# Espressif register map
File version: 1.0
CPU: Xtensa LX6 1, little endian, no MPU, FPU, 3 interrupt priority bits
Registers are 32-bit, access not given, reset 0x0 unless marked. A register's access mark holds for its fields unless they carry their own. Offsets are from the block's base; [hi:lo] are bit positions; {n}, {i} and the like mark numbered series.

## DPORT
Base 0x3FF00000
0x00 PRO_BOOT_REMAP_CTRL — DPORT_PRO_BOOT_REMAP_CTRL
  [0] PRO_BOOT_REMAP
0x04 APP_BOOT_REMAP_CTRL — DPORT_APP_BOOT_REMAP_CTRL
  [0] APP_BOOT_REMAP
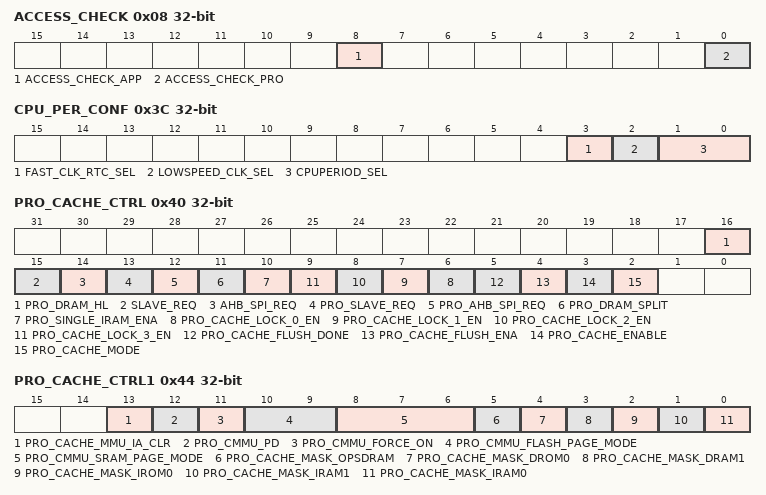
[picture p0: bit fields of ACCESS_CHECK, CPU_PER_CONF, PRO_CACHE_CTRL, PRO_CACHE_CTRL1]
0x08 ACCESS_CHECK — DPORT_ACCESS_CHECK
  [8] ACCESS_CHECK_APP, [0] ACCESS_CHECK_PRO
0x0C PRO_DPORT_APB_MASK0 — DPORT_PRO_DPORT_APB_MASK0
  [31:0] PRODPORT_APB_MASK0
0x10 PRO_DPORT_APB_MASK1 — DPORT_PRO_DPORT_APB_MASK1
  [31:0] PRODPORT_APB_MASK1
0x14 APP_DPORT_APB_MASK0 — DPORT_APP_DPORT_APB_MASK0
  [31:0] APPDPORT_APB_MASK0
0x18 APP_DPORT_APB_MASK1 — DPORT_APP_DPORT_APB_MASK1
  [31:0] APPDPORT_APB_MASK1
0x1C PERI_CLK_EN — DPORT_PERI_CLK_EN
0x20 PERI_RST_EN — DPORT_PERI_RST_EN
0x24 WIFI_BB_CFG — DPORT_WIFI_BB_CFG
0x28 WIFI_BB_CFG_2 — DPORT_WIFI_BB_CFG_2
0x2C APPCPU_CTRL_A — DPORT_APPCPU_CTRL_A
  [0] APPCPU_RESETTING
0x30 APPCPU_CTRL_B — DPORT_APPCPU_CTRL_B
  [0] APPCPU_CLKGATE_EN
0x34 APPCPU_CTRL_C — DPORT_APPCPU_CTRL_C
  [0] APPCPU_RUNSTALL
0x38 APPCPU_CTRL_D — DPORT_APPCPU_CTRL_D
  [31:0] APPCPU_BOOT_ADDR
0x3C CPU_PER_CONF — DPORT_CPU_PER_CONF
  [3] FAST_CLK_RTC_SEL, [2] LOWSPEED_CLK_SEL, [1:0] CPUPERIOD_SEL
0x40 PRO_CACHE_CTRL — DPORT_PRO_CACHE_CTRL
  [16] PRO_DRAM_HL, [15] SLAVE_REQ, [14] AHB_SPI_REQ, [13] PRO_SLAVE_REQ, [12] PRO_AHB_SPI_REQ, [11] PRO_DRAM_SPLIT, [10] PRO_SINGLE_IRAM_ENA, [n+6] PRO_CACHE_LOCK_{n}_EN (n=0..3), [5] PRO_CACHE_FLUSH_DONE, [4] PRO_CACHE_FLUSH_ENA, [3] PRO_CACHE_ENABLE, [2] PRO_CACHE_MODE
0x44 PRO_CACHE_CTRL1 — DPORT_PRO_CACHE_CTRL1
  [13] PRO_CACHE_MMU_IA_CLR, [12] PRO_CMMU_PD, [11] PRO_CMMU_FORCE_ON, [10:9] PRO_CMMU_FLASH_PAGE_MODE, [8:6] PRO_CMMU_SRAM_PAGE_MODE, [5] PRO_CACHE_MASK_OPSDRAM, [4] PRO_CACHE_MASK_DROM0, [3] PRO_CACHE_MASK_DRAM1, [2] PRO_CACHE_MASK_IROM0, [1] PRO_CACHE_MASK_IRAM1, [0] PRO_CACHE_MASK_IRAM0
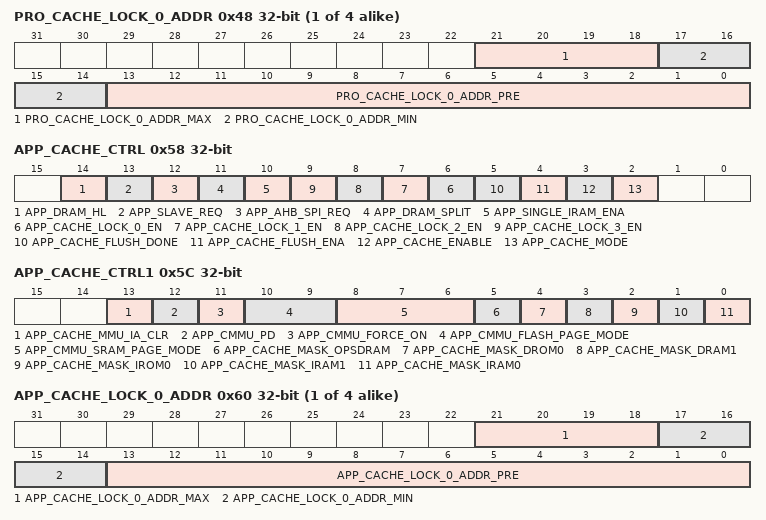
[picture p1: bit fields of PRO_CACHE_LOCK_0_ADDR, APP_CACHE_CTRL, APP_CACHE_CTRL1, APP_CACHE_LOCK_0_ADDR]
{0x48+4i} PRO_CACHE_LOCK_{i}_ADDR (i=0..3) — DPORT_PRO_CACHE_LOCK_{i}_ADDR
  [21:18] PRO_CACHE_LOCK_{i}_ADDR_MAX, [17:14] PRO_CACHE_LOCK_{i}_ADDR_MIN, [13:0] PRO_CACHE_LOCK_{i}_ADDR_PRE
0x58 APP_CACHE_CTRL — DPORT_APP_CACHE_CTRL
  [14] APP_DRAM_HL, [13] APP_SLAVE_REQ, [12] APP_AHB_SPI_REQ, [11] APP_DRAM_SPLIT, [10] APP_SINGLE_IRAM_ENA, [n+6] APP_CACHE_LOCK_{n}_EN (n=0..3), [5] APP_CACHE_FLUSH_DONE, [4] APP_CACHE_FLUSH_ENA, [3] APP_CACHE_ENABLE, [2] APP_CACHE_MODE
0x5C APP_CACHE_CTRL1 — DPORT_APP_CACHE_CTRL1
  [13] APP_CACHE_MMU_IA_CLR, [12] APP_CMMU_PD, [11] APP_CMMU_FORCE_ON, [10:9] APP_CMMU_FLASH_PAGE_MODE, [8:6] APP_CMMU_SRAM_PAGE_MODE, [5] APP_CACHE_MASK_OPSDRAM, [4] APP_CACHE_MASK_DROM0, [3] APP_CACHE_MASK_DRAM1, [2] APP_CACHE_MASK_IROM0, [1] APP_CACHE_MASK_IRAM1, [0] APP_CACHE_MASK_IRAM0
{0x60+4i} APP_CACHE_LOCK_{i}_ADDR (i=0..3) — DPORT_APP_CACHE_LOCK_{i}_ADDR
  [21:18] APP_CACHE_LOCK_{i}_ADDR_MAX, [17:14] APP_CACHE_LOCK_{i}_ADDR_MIN, [13:0] APP_CACHE_LOCK_{i}_ADDR_PRE
0x70 TRACEMEM_MUX_MODE — DPORT_TRACEMEM_MUX_MODE
  [1:0] TRACEMEM_MUX_MODE
0x74 PRO_TRACEMEM_ENA — DPORT_PRO_TRACEMEM_ENA
  [0] PRO_TRACEMEM_ENA
0x78 APP_TRACEMEM_ENA — DPORT_APP_TRACEMEM_ENA
  [0] APP_TRACEMEM_ENA
0x7C CACHE_MUX_MODE — DPORT_CACHE_MUX_MODE
  [1:0] CACHE_MUX_MODE
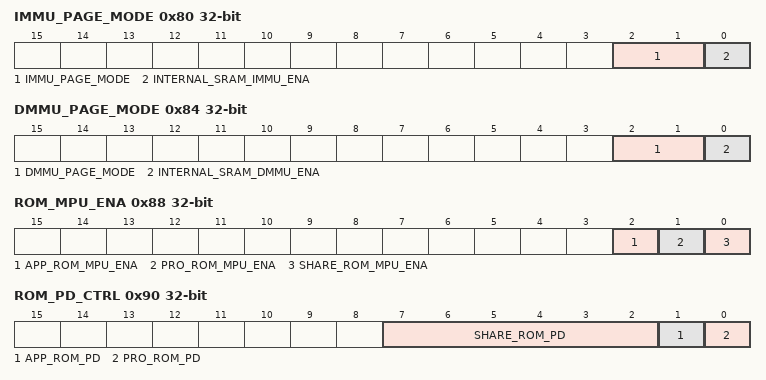
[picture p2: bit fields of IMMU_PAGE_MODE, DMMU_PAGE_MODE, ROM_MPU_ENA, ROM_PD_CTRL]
0x80 IMMU_PAGE_MODE — DPORT_IMMU_PAGE_MODE
  [2:1] IMMU_PAGE_MODE, [0] INTERNAL_SRAM_IMMU_ENA
0x84 DMMU_PAGE_MODE — DPORT_DMMU_PAGE_MODE
  [2:1] DMMU_PAGE_MODE, [0] INTERNAL_SRAM_DMMU_ENA
0x88 ROM_MPU_ENA — DPORT_ROM_MPU_ENA
  [2] APP_ROM_MPU_ENA, [1] PRO_ROM_MPU_ENA, [0] SHARE_ROM_MPU_ENA
0x8C MEM_PD_MASK — DPORT_MEM_PD_MASK
  [0] LSLP_MEM_PD_MASK
0x90 ROM_PD_CTRL — DPORT_ROM_PD_CTRL
  [7:2] SHARE_ROM_PD, [1] APP_ROM_PD, [0] PRO_ROM_PD
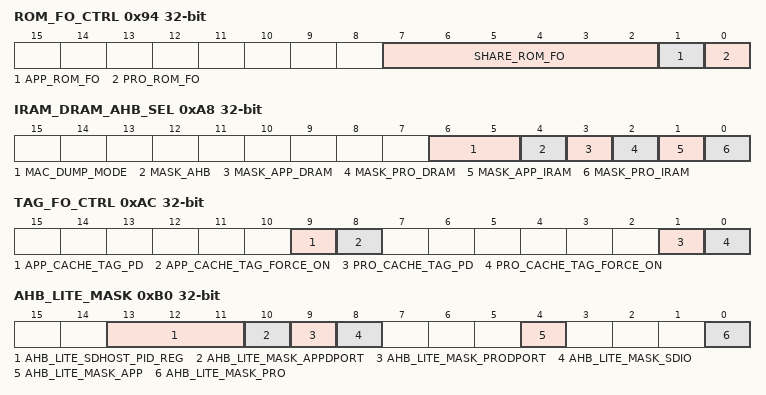
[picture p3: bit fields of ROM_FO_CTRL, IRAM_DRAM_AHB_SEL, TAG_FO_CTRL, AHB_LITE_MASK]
0x94 ROM_FO_CTRL — DPORT_ROM_FO_CTRL
  [7:2] SHARE_ROM_FO, [1] APP_ROM_FO, [0] PRO_ROM_FO
0x98 SRAM_PD_CTRL_0 — DPORT_SRAM_PD_CTRL_0
  [31:0] SRAM_PD_0
0x9C SRAM_PD_CTRL_1 — DPORT_SRAM_PD_CTRL_1
  [0] SRAM_PD_1
0xA0 SRAM_FO_CTRL_0 — DPORT_SRAM_FO_CTRL_0
  [31:0] SRAM_FO_0
0xA4 SRAM_FO_CTRL_1 — DPORT_SRAM_FO_CTRL_1
  [0] SRAM_FO_1
0xA8 IRAM_DRAM_AHB_SEL — DPORT_IRAM_DRAM_AHB_SEL
  [6:5] MAC_DUMP_MODE, [4] MASK_AHB, [3] MASK_APP_DRAM, [2] MASK_PRO_DRAM, [1] MASK_APP_IRAM, [0] MASK_PRO_IRAM
0xAC TAG_FO_CTRL — DPORT_TAG_FO_CTRL
  [9] APP_CACHE_TAG_PD, [8] APP_CACHE_TAG_FORCE_ON, [1] PRO_CACHE_TAG_PD, [0] PRO_CACHE_TAG_FORCE_ON
0xB0 AHB_LITE_MASK — DPORT_AHB_LITE_MASK
  [13:11] AHB_LITE_SDHOST_PID_REG, [10] AHB_LITE_MASK_APPDPORT, [9] AHB_LITE_MASK_PRODPORT, [8] AHB_LITE_MASK_SDIO, [4] AHB_LITE_MASK_APP, [0] AHB_LITE_MASK_PRO
0xB4 AHB_MPU_TABLE_0 — DPORT_AHB_MPU_TABLE_0
  [31:0] AHB_ACCESS_GRANT_0
0xB8 AHB_MPU_TABLE_1 — DPORT_AHB_MPU_TABLE_1
  [8:0] AHB_ACCESS_GRANT_1
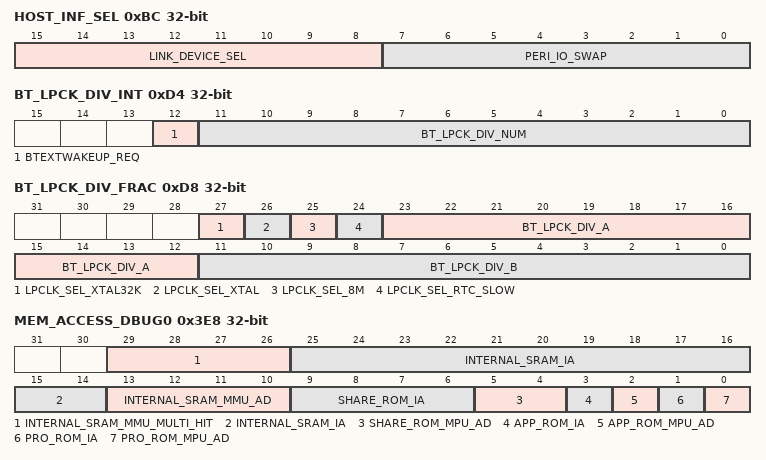
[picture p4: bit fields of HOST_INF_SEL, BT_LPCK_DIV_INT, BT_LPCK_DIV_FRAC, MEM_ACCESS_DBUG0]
0xBC HOST_INF_SEL — DPORT_HOST_INF_SEL
  [15:8] LINK_DEVICE_SEL, [7:0] PERI_IO_SWAP
0xC0 PERIP_CLK_EN — DPORT_PERIP_CLK_EN
0xC4 PERIP_RST_EN — DPORT_PERIP_RST_EN
  [12] SPI_DECRYPT_ENABLE, [8] SPI_ENCRYPT_ENABLE, [4] SLAVE_SPI_MASK_APP, [31:0] PERIP_RST, [0] SLAVE_SPI_MASK_PRO
0xCC WIFI_CLK_EN — DPORT_WIFI_CLK_EN
0xD0 CORE_RST_EN — DPORT_CORE_RST_EN
  [31:0] CORE_RST
0xD4 BT_LPCK_DIV_INT — DPORT_BT_LPCK_DIV_INT
  [12] BTEXTWAKEUP_REQ, [11:0] BT_LPCK_DIV_NUM
0xD8 BT_LPCK_DIV_FRAC — DPORT_BT_LPCK_DIV_FRAC
  [27] LPCLK_SEL_XTAL32K, [26] LPCLK_SEL_XTAL, [25] LPCLK_SEL_8M, [24] LPCLK_SEL_RTC_SLOW, [23:12] BT_LPCK_DIV_A, [11:0] BT_LPCK_DIV_B
{0xDC+4i} CPU_INTR_FROM_CPU_{i} (i=0..3) — DPORT_CPU_INTR_FROM_CPU_{i}
  [0] CPU_INTR_FROM_CPU_{i}
{0xEC+4i} PRO_INTR_STATUS_{i} (i=0..2) — DPORT_PRO_INTR_STATUS_{i}
{0xF8+4i} APP_INTR_STATUS_{i} (i=0..2) — DPORT_APP_INTR_STATUS_{i}
0x104 PRO_MAC_INTR_MAP — DPORT_PRO_MAC_INTR_MAP
  [4:0] PRO_MAC_INTR_MAP
0x108 PRO_MAC_NMI_MAP — DPORT_PRO_MAC_NMI_MAP
  [4:0] PRO_MAC_NMI_MAP
0x10C PRO_BB_INT_MAP — DPORT_PRO_BB_INT_MAP
  [4:0] PRO_BB_INT_MAP
0x110 PRO_BT_MAC_INT_MAP — DPORT_PRO_BT_MAC_INT_MAP
  [4:0] PRO_BT_MAC_INT_MAP
0x114 PRO_BT_BB_INT_MAP — DPORT_PRO_BT_BB_INT_MAP
  [4:0] PRO_BT_BB_INT_MAP
0x118 PRO_BT_BB_NMI_MAP — DPORT_PRO_BT_BB_NMI_MAP
  [4:0] PRO_BT_BB_NMI_MAP
0x11C PRO_RWBT_IRQ_MAP — DPORT_PRO_RWBT_IRQ_MAP
  [4:0] PRO_RWBT_IRQ_MAP
0x120 PRO_RWBLE_IRQ_MAP — DPORT_PRO_RWBLE_IRQ_MAP
  [4:0] PRO_RWBLE_IRQ_MAP
0x124 PRO_RWBT_NMI_MAP — DPORT_PRO_RWBT_NMI_MAP
  [4:0] PRO_RWBT_NMI_MAP
0x128 PRO_RWBLE_NMI_MAP — DPORT_PRO_RWBLE_NMI_MAP
  [4:0] PRO_RWBLE_NMI_MAP
0x12C PRO_SLC0_INTR_MAP — DPORT_PRO_SLC0_INTR_MAP
  [4:0] PRO_SLC0_INTR_MAP
0x130 PRO_SLC1_INTR_MAP — DPORT_PRO_SLC1_INTR_MAP
  [4:0] PRO_SLC1_INTR_MAP
0x134 PRO_UHCI0_INTR_MAP — DPORT_PRO_UHCI0_INTR_MAP
  [4:0] PRO_UHCI0_INTR_MAP
0x138 PRO_UHCI1_INTR_MAP — DPORT_PRO_UHCI1_INTR_MAP
  [4:0] PRO_UHCI1_INTR_MAP
0x13C PRO_TG_T0_LEVEL_INT_MAP — DPORT_PRO_TG_T0_LEVEL_INT_MAP
  [4:0] PRO_TG_T0_LEVEL_INT_MAP
0x140 PRO_TG_T1_LEVEL_INT_MAP — DPORT_PRO_TG_T1_LEVEL_INT_MAP
  [4:0] PRO_TG_T1_LEVEL_INT_MAP
0x144 PRO_TG_WDT_LEVEL_INT_MAP — DPORT_PRO_TG_WDT_LEVEL_INT_MAP
  [4:0] PRO_TG_WDT_LEVEL_INT_MAP
0x148 PRO_TG_LACT_LEVEL_INT_MAP — DPORT_PRO_TG_LACT_LEVEL_INT_MAP
  [4:0] PRO_TG_LACT_LEVEL_INT_MAP
0x14C PRO_TG1_T0_LEVEL_INT_MAP — DPORT_PRO_TG1_T0_LEVEL_INT_MAP
  [4:0] PRO_TG1_T0_LEVEL_INT_MAP
0x150 PRO_TG1_T1_LEVEL_INT_MAP — DPORT_PRO_TG1_T1_LEVEL_INT_MAP
  [4:0] PRO_TG1_T1_LEVEL_INT_MAP
0x154 PRO_TG1_WDT_LEVEL_INT_MAP — DPORT_PRO_TG1_WDT_LEVEL_INT_MAP
  [4:0] PRO_TG1_WDT_LEVEL_INT_MAP
0x158 PRO_TG1_LACT_LEVEL_INT_MAP — DPORT_PRO_TG1_LACT_LEVEL_INT_MAP
  [4:0] PRO_TG1_LACT_LEVEL_INT_MAP
0x15C PRO_GPIO_INTERRUPT_MAP — DPORT_PRO_GPIO_INTERRUPT_MAP
  [4:0] PRO_GPIO_INTERRUPT_PRO_MAP
0x160 PRO_GPIO_INTERRUPT_NMI_MAP — DPORT_PRO_GPIO_INTERRUPT_NMI_MAP
  [4:0] PRO_GPIO_INTERRUPT_PRO_NMI_MAP
{0x164+4i} PRO_CPU_INTR_FROM_CPU_{i}_MAP (i=0..3) — DPORT_PRO_CPU_INTR_FROM_CPU_{i}_MAP
  [4:0] PRO_CPU_INTR_FROM_CPU_{i}_MAP
{0x174+4i} PRO_SPI_INTR_{i}_MAP (i=0..3) — DPORT_PRO_SPI_INTR_{i}_MAP
  [4:0] PRO_SPI_INTR_{i}_MAP
0x184 PRO_I2S0_INT_MAP — DPORT_PRO_I2S0_INT_MAP
  [4:0] PRO_I2S0_INT_MAP
0x188 PRO_I2S1_INT_MAP — DPORT_PRO_I2S1_INT_MAP
  [4:0] PRO_I2S1_INT_MAP
0x18C PRO_UART_INTR_MAP — DPORT_PRO_UART_INTR_MAP
  [4:0] PRO_UART_INTR_MAP
0x190 PRO_UART1_INTR_MAP — DPORT_PRO_UART1_INTR_MAP
  [4:0] PRO_UART1_INTR_MAP
0x194 PRO_UART2_INTR_MAP — DPORT_PRO_UART2_INTR_MAP
  [4:0] PRO_UART2_INTR_MAP
0x198 PRO_SDIO_HOST_INTERRUPT_MAP — DPORT_PRO_SDIO_HOST_INTERRUPT_MAP
  [4:0] PRO_SDIO_HOST_INTERRUPT_MAP
0x19C PRO_EMAC_INT_MAP — DPORT_PRO_EMAC_INT_MAP
  [4:0] PRO_EMAC_INT_MAP
{0x1A0+4i} PRO_PWM{i}_INTR_MAP (i=0..3) — DPORT_PRO_PWM{i}_INTR_MAP
  [4:0] PRO_PWM{i}_INTR_MAP
0x1B0 PRO_LEDC_INT_MAP — DPORT_PRO_LEDC_INT_MAP
  [4:0] PRO_LEDC_INT_MAP
0x1B4 PRO_EFUSE_INT_MAP — DPORT_PRO_EFUSE_INT_MAP
  [4:0] PRO_EFUSE_INT_MAP
0x1B8 PRO_CAN_INT_MAP — DPORT_PRO_CAN_INT_MAP
  [4:0] PRO_CAN_INT_MAP
0x1BC PRO_RTC_CORE_INTR_MAP — DPORT_PRO_RTC_CORE_INTR_MAP
  [4:0] PRO_RTC_CORE_INTR_MAP
0x1C0 PRO_RMT_INTR_MAP — DPORT_PRO_RMT_INTR_MAP
  [4:0] PRO_RMT_INTR_MAP
0x1C4 PRO_PCNT_INTR_MAP — DPORT_PRO_PCNT_INTR_MAP
  [4:0] PRO_PCNT_INTR_MAP
0x1C8 PRO_I2C_EXT0_INTR_MAP — DPORT_PRO_I2C_EXT0_INTR_MAP
  [4:0] PRO_I2C_EXT0_INTR_MAP
0x1CC PRO_I2C_EXT1_INTR_MAP — DPORT_PRO_I2C_EXT1_INTR_MAP
  [4:0] PRO_I2C_EXT1_INTR_MAP
0x1D0 PRO_RSA_INTR_MAP — DPORT_PRO_RSA_INTR_MAP
  [4:0] PRO_RSA_INTR_MAP
{0x1D0+4i} PRO_SPI{i}_DMA_INT_MAP (i=1..3) — DPORT_PRO_SPI{i}_DMA_INT_MAP
  [4:0] PRO_SPI{i}_DMA_INT_MAP
0x1E0 PRO_WDG_INT_MAP — DPORT_PRO_WDG_INT_MAP
  [4:0] PRO_WDG_INT_MAP
0x1E4 PRO_TIMER_INT1_MAP — DPORT_PRO_TIMER_INT1_MAP
  [4:0] PRO_TIMER_INT1_MAP
0x1E8 PRO_TIMER_INT2_MAP — DPORT_PRO_TIMER_INT2_MAP
  [4:0] PRO_TIMER_INT2_MAP
0x1EC PRO_TG_T0_EDGE_INT_MAP — DPORT_PRO_TG_T0_EDGE_INT_MAP
  [4:0] PRO_TG_T0_EDGE_INT_MAP
0x1F0 PRO_TG_T1_EDGE_INT_MAP — DPORT_PRO_TG_T1_EDGE_INT_MAP
  [4:0] PRO_TG_T1_EDGE_INT_MAP
0x1F4 PRO_TG_WDT_EDGE_INT_MAP — DPORT_PRO_TG_WDT_EDGE_INT_MAP
  [4:0] PRO_TG_WDT_EDGE_INT_MAP
0x1F8 PRO_TG_LACT_EDGE_INT_MAP — DPORT_PRO_TG_LACT_EDGE_INT_MAP
  [4:0] PRO_TG_LACT_EDGE_INT_MAP
0x1FC PRO_TG1_T0_EDGE_INT_MAP — DPORT_PRO_TG1_T0_EDGE_INT_MAP
  [4:0] PRO_TG1_T0_EDGE_INT_MAP
0x200 PRO_TG1_T1_EDGE_INT_MAP — DPORT_PRO_TG1_T1_EDGE_INT_MAP
  [4:0] PRO_TG1_T1_EDGE_INT_MAP
0x204 PRO_TG1_WDT_EDGE_INT_MAP — DPORT_PRO_TG1_WDT_EDGE_INT_MAP
  [4:0] PRO_TG1_WDT_EDGE_INT_MAP
0x208 PRO_TG1_LACT_EDGE_INT_MAP — DPORT_PRO_TG1_LACT_EDGE_INT_MAP
  [4:0] PRO_TG1_LACT_EDGE_INT_MAP
0x20C PRO_MMU_IA_INT_MAP — DPORT_PRO_MMU_IA_INT_MAP
  [4:0] PRO_MMU_IA_INT_MAP
0x210 PRO_MPU_IA_INT_MAP — DPORT_PRO_MPU_IA_INT_MAP
  [4:0] PRO_MPU_IA_INT_MAP
0x214 PRO_CACHE_IA_INT_MAP — DPORT_PRO_CACHE_IA_INT_MAP
  [4:0] PRO_CACHE_IA_INT_MAP
0x218 APP_MAC_INTR_MAP — DPORT_APP_MAC_INTR_MAP
  [4:0] APP_MAC_INTR_MAP
0x21C APP_MAC_NMI_MAP — DPORT_APP_MAC_NMI_MAP
  [4:0] APP_MAC_NMI_MAP
0x220 APP_BB_INT_MAP — DPORT_APP_BB_INT_MAP
  [4:0] APP_BB_INT_MAP
0x224 APP_BT_MAC_INT_MAP — DPORT_APP_BT_MAC_INT_MAP
  [4:0] APP_BT_MAC_INT_MAP
0x228 APP_BT_BB_INT_MAP — DPORT_APP_BT_BB_INT_MAP
  [4:0] APP_BT_BB_INT_MAP
0x22C APP_BT_BB_NMI_MAP — DPORT_APP_BT_BB_NMI_MAP
  [4:0] APP_BT_BB_NMI_MAP
0x230 APP_RWBT_IRQ_MAP — DPORT_APP_RWBT_IRQ_MAP
  [4:0] APP_RWBT_IRQ_MAP
0x234 APP_RWBLE_IRQ_MAP — DPORT_APP_RWBLE_IRQ_MAP
  [4:0] APP_RWBLE_IRQ_MAP
0x238 APP_RWBT_NMI_MAP — DPORT_APP_RWBT_NMI_MAP
  [4:0] APP_RWBT_NMI_MAP
0x23C APP_RWBLE_NMI_MAP — DPORT_APP_RWBLE_NMI_MAP
  [4:0] APP_RWBLE_NMI_MAP
0x240 APP_SLC0_INTR_MAP — DPORT_APP_SLC0_INTR_MAP
  [4:0] APP_SLC0_INTR_MAP
0x244 APP_SLC1_INTR_MAP — DPORT_APP_SLC1_INTR_MAP
  [4:0] APP_SLC1_INTR_MAP
0x248 APP_UHCI0_INTR_MAP — DPORT_APP_UHCI0_INTR_MAP
  [4:0] APP_UHCI0_INTR_MAP
0x24C APP_UHCI1_INTR_MAP — DPORT_APP_UHCI1_INTR_MAP
  [4:0] APP_UHCI1_INTR_MAP
0x250 APP_TG_T0_LEVEL_INT_MAP — DPORT_APP_TG_T0_LEVEL_INT_MAP
  [4:0] APP_TG_T0_LEVEL_INT_MAP
0x254 APP_TG_T1_LEVEL_INT_MAP — DPORT_APP_TG_T1_LEVEL_INT_MAP
  [4:0] APP_TG_T1_LEVEL_INT_MAP
0x258 APP_TG_WDT_LEVEL_INT_MAP — DPORT_APP_TG_WDT_LEVEL_INT_MAP
  [4:0] APP_TG_WDT_LEVEL_INT_MAP
0x25C APP_TG_LACT_LEVEL_INT_MAP — DPORT_APP_TG_LACT_LEVEL_INT_MAP
  [4:0] APP_TG_LACT_LEVEL_INT_MAP
0x260 APP_TG1_T0_LEVEL_INT_MAP — DPORT_APP_TG1_T0_LEVEL_INT_MAP
  [4:0] APP_TG1_T0_LEVEL_INT_MAP
0x264 APP_TG1_T1_LEVEL_INT_MAP — DPORT_APP_TG1_T1_LEVEL_INT_MAP
  [4:0] APP_TG1_T1_LEVEL_INT_MAP
0x268 APP_TG1_WDT_LEVEL_INT_MAP — DPORT_APP_TG1_WDT_LEVEL_INT_MAP
  [4:0] APP_TG1_WDT_LEVEL_INT_MAP
0x26C APP_TG1_LACT_LEVEL_INT_MAP — DPORT_APP_TG1_LACT_LEVEL_INT_MAP
  [4:0] APP_TG1_LACT_LEVEL_INT_MAP
0x270 APP_GPIO_INTERRUPT_MAP — DPORT_APP_GPIO_INTERRUPT_MAP
  [4:0] APP_GPIO_INTERRUPT_APP_MAP
0x274 APP_GPIO_INTERRUPT_NMI_MAP — DPORT_APP_GPIO_INTERRUPT_NMI_MAP
  [4:0] APP_GPIO_INTERRUPT_APP_NMI_MAP
{0x278+4i} APP_CPU_INTR_FROM_CPU_{i}_MAP (i=0..3) — DPORT_APP_CPU_INTR_FROM_CPU_{i}_MAP
  [4:0] APP_CPU_INTR_FROM_CPU_{i}_MAP
{0x288+4i} APP_SPI_INTR_{i}_MAP (i=0..3) — DPORT_APP_SPI_INTR_{i}_MAP
  [4:0] APP_SPI_INTR_{i}_MAP
0x298 APP_I2S0_INT_MAP — DPORT_APP_I2S0_INT_MAP
  [4:0] APP_I2S0_INT_MAP
0x29C APP_I2S1_INT_MAP — DPORT_APP_I2S1_INT_MAP
  [4:0] APP_I2S1_INT_MAP
0x2A0 APP_UART_INTR_MAP — DPORT_APP_UART_INTR_MAP
  [4:0] APP_UART_INTR_MAP
0x2A4 APP_UART1_INTR_MAP — DPORT_APP_UART1_INTR_MAP
  [4:0] APP_UART1_INTR_MAP
0x2A8 APP_UART2_INTR_MAP — DPORT_APP_UART2_INTR_MAP
  [4:0] APP_UART2_INTR_MAP
0x2AC APP_SDIO_HOST_INTERRUPT_MAP — DPORT_APP_SDIO_HOST_INTERRUPT_MAP
  [4:0] APP_SDIO_HOST_INTERRUPT_MAP
0x2B0 APP_EMAC_INT_MAP — DPORT_APP_EMAC_INT_MAP
  [4:0] APP_EMAC_INT_MAP
{0x2B4+4i} APP_PWM{i}_INTR_MAP (i=0..3) — DPORT_APP_PWM{i}_INTR_MAP
  [4:0] APP_PWM{i}_INTR_MAP
0x2C4 APP_LEDC_INT_MAP — DPORT_APP_LEDC_INT_MAP
  [4:0] APP_LEDC_INT_MAP
0x2C8 APP_EFUSE_INT_MAP — DPORT_APP_EFUSE_INT_MAP
  [4:0] APP_EFUSE_INT_MAP
0x2CC APP_CAN_INT_MAP — DPORT_APP_CAN_INT_MAP
  [4:0] APP_CAN_INT_MAP
0x2D0 APP_RTC_CORE_INTR_MAP — DPORT_APP_RTC_CORE_INTR_MAP
  [4:0] APP_RTC_CORE_INTR_MAP
0x2D4 APP_RMT_INTR_MAP — DPORT_APP_RMT_INTR_MAP
  [4:0] APP_RMT_INTR_MAP
0x2D8 APP_PCNT_INTR_MAP — DPORT_APP_PCNT_INTR_MAP
  [4:0] APP_PCNT_INTR_MAP
0x2DC APP_I2C_EXT0_INTR_MAP — DPORT_APP_I2C_EXT0_INTR_MAP
  [4:0] APP_I2C_EXT0_INTR_MAP
0x2E0 APP_I2C_EXT1_INTR_MAP — DPORT_APP_I2C_EXT1_INTR_MAP
  [4:0] APP_I2C_EXT1_INTR_MAP
0x2E4 APP_RSA_INTR_MAP — DPORT_APP_RSA_INTR_MAP
  [4:0] APP_RSA_INTR_MAP
{0x2E4+4i} APP_SPI{i}_DMA_INT_MAP (i=1..3) — DPORT_APP_SPI{i}_DMA_INT_MAP
  [4:0] APP_SPI{i}_DMA_INT_MAP
0x2F4 APP_WDG_INT_MAP — DPORT_APP_WDG_INT_MAP
  [4:0] APP_WDG_INT_MAP
0x2F8 APP_TIMER_INT1_MAP — DPORT_APP_TIMER_INT1_MAP
  [4:0] APP_TIMER_INT1_MAP
0x2FC APP_TIMER_INT2_MAP — DPORT_APP_TIMER_INT2_MAP
  [4:0] APP_TIMER_INT2_MAP
0x300 APP_TG_T0_EDGE_INT_MAP — DPORT_APP_TG_T0_EDGE_INT_MAP
  [4:0] APP_TG_T0_EDGE_INT_MAP
0x304 APP_TG_T1_EDGE_INT_MAP — DPORT_APP_TG_T1_EDGE_INT_MAP
  [4:0] APP_TG_T1_EDGE_INT_MAP
0x308 APP_TG_WDT_EDGE_INT_MAP — DPORT_APP_TG_WDT_EDGE_INT_MAP
  [4:0] APP_TG_WDT_EDGE_INT_MAP
0x30C APP_TG_LACT_EDGE_INT_MAP — DPORT_APP_TG_LACT_EDGE_INT_MAP
  [4:0] APP_TG_LACT_EDGE_INT_MAP
0x310 APP_TG1_T0_EDGE_INT_MAP — DPORT_APP_TG1_T0_EDGE_INT_MAP
  [4:0] APP_TG1_T0_EDGE_INT_MAP
0x314 APP_TG1_T1_EDGE_INT_MAP — DPORT_APP_TG1_T1_EDGE_INT_MAP
  [4:0] APP_TG1_T1_EDGE_INT_MAP
0x318 APP_TG1_WDT_EDGE_INT_MAP — DPORT_APP_TG1_WDT_EDGE_INT_MAP
  [4:0] APP_TG1_WDT_EDGE_INT_MAP
0x31C APP_TG1_LACT_EDGE_INT_MAP — DPORT_APP_TG1_LACT_EDGE_INT_MAP
  [4:0] APP_TG1_LACT_EDGE_INT_MAP
0x320 APP_MMU_IA_INT_MAP — DPORT_APP_MMU_IA_INT_MAP
  [4:0] APP_MMU_IA_INT_MAP
0x324 APP_MPU_IA_INT_MAP — DPORT_APP_MPU_IA_INT_MAP
  [4:0] APP_MPU_IA_INT_MAP
0x328 APP_CACHE_IA_INT_MAP — DPORT_APP_CACHE_IA_INT_MAP
  [4:0] APP_CACHE_IA_INT_MAP
0x32C AHBLITE_MPU_TABLE_UART — DPORT_AHBLITE_MPU_TABLE_UART
  [5:0] UART_ACCESS_GRANT_CONFIG
0x330 AHBLITE_MPU_TABLE_SPI1 — DPORT_AHBLITE_MPU_TABLE_SPI1
  [5:0] SPI1_ACCESS_GRANT_CONFIG
0x334 AHBLITE_MPU_TABLE_SPI0 — DPORT_AHBLITE_MPU_TABLE_SPI0
  [5:0] SPI0_ACCESS_GRANT_CONFIG
0x338 AHBLITE_MPU_TABLE_GPIO — DPORT_AHBLITE_MPU_TABLE_GPIO
  [5:0] GPIO_ACCESS_GRANT_CONFIG
0x33C AHBLITE_MPU_TABLE_FE2 — DPORT_AHBLITE_MPU_TABLE_FE2
  [5:0] FE2_ACCESS_GRANT_CONFIG
0x340 AHBLITE_MPU_TABLE_FE — DPORT_AHBLITE_MPU_TABLE_FE
  [5:0] FE_ACCESS_GRANT_CONFIG
0x344 AHBLITE_MPU_TABLE_TIMER — DPORT_AHBLITE_MPU_TABLE_TIMER
  [5:0] TIMER_ACCESS_GRANT_CONFIG
0x348 AHBLITE_MPU_TABLE_RTC — DPORT_AHBLITE_MPU_TABLE_RTC
  [5:0] RTC_ACCESS_GRANT_CONFIG
0x34C AHBLITE_MPU_TABLE_IO_MUX — DPORT_AHBLITE_MPU_TABLE_IO_MUX
  [5:0] IOMUX_ACCESS_GRANT_CONFIG
0x350 AHBLITE_MPU_TABLE_WDG — DPORT_AHBLITE_MPU_TABLE_WDG
  [5:0] WDG_ACCESS_GRANT_CONFIG
0x354 AHBLITE_MPU_TABLE_HINF — DPORT_AHBLITE_MPU_TABLE_HINF
  [5:0] HINF_ACCESS_GRANT_CONFIG
0x358 AHBLITE_MPU_TABLE_UHCI1 — DPORT_AHBLITE_MPU_TABLE_UHCI1
  [5:0] UHCI1_ACCESS_GRANT_CONFIG
0x35C AHBLITE_MPU_TABLE_MISC — DPORT_AHBLITE_MPU_TABLE_MISC
  [5:0] MISC_ACCESS_GRANT_CONFIG
0x360 AHBLITE_MPU_TABLE_I2C — DPORT_AHBLITE_MPU_TABLE_I2C
  [5:0] I2C_ACCESS_GRANT_CONFIG
0x364 AHBLITE_MPU_TABLE_I2S0 — DPORT_AHBLITE_MPU_TABLE_I2S0
  [5:0] I2S0_ACCESS_GRANT_CONFIG
0x368 AHBLITE_MPU_TABLE_UART1 — DPORT_AHBLITE_MPU_TABLE_UART1
  [5:0] UART1_ACCESS_GRANT_CONFIG
0x36C AHBLITE_MPU_TABLE_BT — DPORT_AHBLITE_MPU_TABLE_BT
  [5:0] BT_ACCESS_GRANT_CONFIG
0x370 AHBLITE_MPU_TABLE_BT_BUFFER — DPORT_AHBLITE_MPU_TABLE_BT_BUFFER
  [5:0] BTBUFFER_ACCESS_GRANT_CONFIG
0x374 AHBLITE_MPU_TABLE_I2C_EXT0 — DPORT_AHBLITE_MPU_TABLE_I2C_EXT0
  [5:0] I2CEXT0_ACCESS_GRANT_CONFIG
0x378 AHBLITE_MPU_TABLE_UHCI0 — DPORT_AHBLITE_MPU_TABLE_UHCI0
  [5:0] UHCI0_ACCESS_GRANT_CONFIG
0x37C AHBLITE_MPU_TABLE_SLCHOST — DPORT_AHBLITE_MPU_TABLE_SLCHOST
  [5:0] SLCHOST_ACCESS_GRANT_CONFIG
0x380 AHBLITE_MPU_TABLE_RMT — DPORT_AHBLITE_MPU_TABLE_RMT
  [5:0] RMT_ACCESS_GRANT_CONFIG
0x384 AHBLITE_MPU_TABLE_PCNT — DPORT_AHBLITE_MPU_TABLE_PCNT
  [5:0] PCNT_ACCESS_GRANT_CONFIG
0x388 AHBLITE_MPU_TABLE_SLC — DPORT_AHBLITE_MPU_TABLE_SLC
  [5:0] SLC_ACCESS_GRANT_CONFIG
0x38C AHBLITE_MPU_TABLE_LEDC — DPORT_AHBLITE_MPU_TABLE_LEDC
  [5:0] LEDC_ACCESS_GRANT_CONFIG
0x390 AHBLITE_MPU_TABLE_EFUSE — DPORT_AHBLITE_MPU_TABLE_EFUSE
  [5:0] EFUSE_ACCESS_GRANT_CONFIG
0x394 AHBLITE_MPU_TABLE_SPI_ENCRYPT — DPORT_AHBLITE_MPU_TABLE_SPI_ENCRYPT
  [5:0] SPI_ENCRYPY_ACCESS_GRANT_CONFIG
0x398 AHBLITE_MPU_TABLE_BB — DPORT_AHBLITE_MPU_TABLE_BB
  [5:0] BB_ACCESS_GRANT_CONFIG
0x39C AHBLITE_MPU_TABLE_PWM0 — DPORT_AHBLITE_MPU_TABLE_PWM0
  [5:0] PWM0_ACCESS_GRANT_CONFIG
0x3A0 AHBLITE_MPU_TABLE_TIMERGROUP — DPORT_AHBLITE_MPU_TABLE_TIMERGROUP
  [5:0] TIMERGROUP_ACCESS_GRANT_CONFIG
0x3A4 AHBLITE_MPU_TABLE_TIMERGROUP1 — DPORT_AHBLITE_MPU_TABLE_TIMERGROUP1
  [5:0] TIMERGROUP1_ACCESS_GRANT_CONFIG
0x3A8 AHBLITE_MPU_TABLE_SPI2 — DPORT_AHBLITE_MPU_TABLE_SPI2
  [5:0] SPI2_ACCESS_GRANT_CONFIG
0x3AC AHBLITE_MPU_TABLE_SPI3 — DPORT_AHBLITE_MPU_TABLE_SPI3
  [5:0] SPI3_ACCESS_GRANT_CONFIG
0x3B0 AHBLITE_MPU_TABLE_APB_CTRL — DPORT_AHBLITE_MPU_TABLE_APB_CTRL
  [5:0] APBCTRL_ACCESS_GRANT_CONFIG
0x3B4 AHBLITE_MPU_TABLE_I2C_EXT1 — DPORT_AHBLITE_MPU_TABLE_I2C_EXT1
  [5:0] I2CEXT1_ACCESS_GRANT_CONFIG
0x3B8 AHBLITE_MPU_TABLE_SDIO_HOST — DPORT_AHBLITE_MPU_TABLE_SDIO_HOST
  [5:0] SDIOHOST_ACCESS_GRANT_CONFIG
0x3BC AHBLITE_MPU_TABLE_EMAC — DPORT_AHBLITE_MPU_TABLE_EMAC
  [5:0] EMAC_ACCESS_GRANT_CONFIG
0x3C0 AHBLITE_MPU_TABLE_CAN — DPORT_AHBLITE_MPU_TABLE_CAN
  [5:0] CAN_ACCESS_GRANT_CONFIG
0x3C4 AHBLITE_MPU_TABLE_PWM1 — DPORT_AHBLITE_MPU_TABLE_PWM1
  [5:0] PWM1_ACCESS_GRANT_CONFIG
0x3C8 AHBLITE_MPU_TABLE_I2S1 — DPORT_AHBLITE_MPU_TABLE_I2S1
  [5:0] I2S1_ACCESS_GRANT_CONFIG
0x3CC AHBLITE_MPU_TABLE_UART2 — DPORT_AHBLITE_MPU_TABLE_UART2
  [5:0] UART2_ACCESS_GRANT_CONFIG
0x3D0 AHBLITE_MPU_TABLE_PWM2 — DPORT_AHBLITE_MPU_TABLE_PWM2
  [5:0] PWM2_ACCESS_GRANT_CONFIG
0x3D4 AHBLITE_MPU_TABLE_PWM3 — DPORT_AHBLITE_MPU_TABLE_PWM3
  [5:0] PWM3_ACCESS_GRANT_CONFIG
0x3D8 AHBLITE_MPU_TABLE_RWBT — DPORT_AHBLITE_MPU_TABLE_RWBT
  [5:0] RWBT_ACCESS_GRANT_CONFIG
0x3DC AHBLITE_MPU_TABLE_BTMAC — DPORT_AHBLITE_MPU_TABLE_BTMAC
  [5:0] BTMAC_ACCESS_GRANT_CONFIG
0x3E0 AHBLITE_MPU_TABLE_WIFIMAC — DPORT_AHBLITE_MPU_TABLE_WIFIMAC
  [5:0] WIFIMAC_ACCESS_GRANT_CONFIG
0x3E4 AHBLITE_MPU_TABLE_PWR — DPORT_AHBLITE_MPU_TABLE_PWR
  [5:0] PWR_ACCESS_GRANT_CONFIG
0x3E8 MEM_ACCESS_DBUG0 — DPORT_MEM_ACCESS_DBUG0
  [29:26] INTERNAL_SRAM_MMU_MULTI_HIT, [25:14] INTERNAL_SRAM_IA, [13:10] INTERNAL_SRAM_MMU_AD, [9:6] SHARE_ROM_IA, [5:4] SHARE_ROM_MPU_AD, [3] APP_ROM_IA, [2] APP_ROM_MPU_AD, [1] PRO_ROM_IA, [0] PRO_ROM_MPU_AD
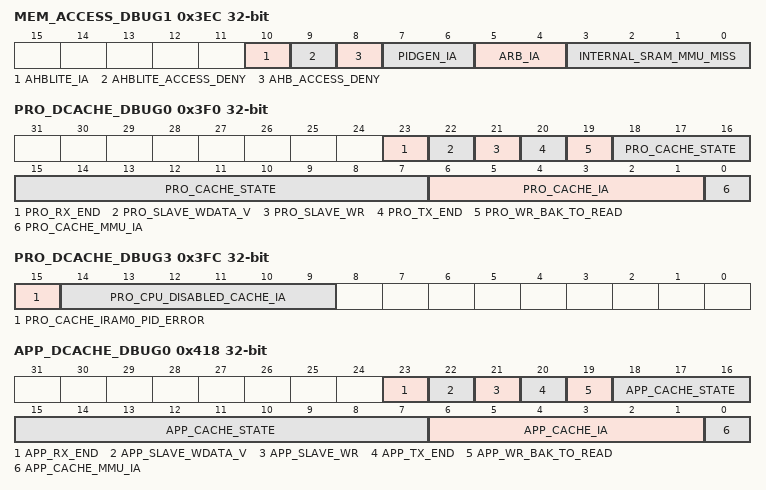
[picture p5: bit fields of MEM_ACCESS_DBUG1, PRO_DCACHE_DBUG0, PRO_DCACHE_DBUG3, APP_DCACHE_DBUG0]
0x3EC MEM_ACCESS_DBUG1 — DPORT_MEM_ACCESS_DBUG1
  [10] AHBLITE_IA, [9] AHBLITE_ACCESS_DENY, [8] AHB_ACCESS_DENY, [7:6] PIDGEN_IA, [5:4] ARB_IA, [3:0] INTERNAL_SRAM_MMU_MISS
0x3F0 PRO_DCACHE_DBUG0 — DPORT_PRO_DCACHE_DBUG0
  [23] PRO_RX_END, [22] PRO_SLAVE_WDATA_V, [21] PRO_SLAVE_WR, [20] PRO_TX_END, [19] PRO_WR_BAK_TO_READ, [18:7] PRO_CACHE_STATE, [6:1] PRO_CACHE_IA, [0] PRO_CACHE_MMU_IA
0x3F4 PRO_DCACHE_DBUG1 — DPORT_PRO_DCACHE_DBUG1
  [31:0] PRO_CTAG_RAM_RDATA
0x3F8 PRO_DCACHE_DBUG2 — DPORT_PRO_DCACHE_DBUG2
  [26:0] PRO_CACHE_VADDR
0x3FC PRO_DCACHE_DBUG3 — DPORT_PRO_DCACHE_DBUG3
  [15] PRO_CACHE_IRAM0_PID_ERROR, [14:9] PRO_CPU_DISABLED_CACHE_IA
0x400 PRO_DCACHE_DBUG4 — DPORT_PRO_DCACHE_DBUG4
  [19:0] PRO_DRAM1ADDR0_IA
0x404 PRO_DCACHE_DBUG5 — DPORT_PRO_DCACHE_DBUG5
  [19:0] PRO_DROM0ADDR0_IA
0x408 PRO_DCACHE_DBUG6 — DPORT_PRO_DCACHE_DBUG6
  [19:0] PRO_IRAM0ADDR_IA
0x40C PRO_DCACHE_DBUG7 — DPORT_PRO_DCACHE_DBUG7
  [19:0] PRO_IRAM1ADDR_IA
0x410 PRO_DCACHE_DBUG8 — DPORT_PRO_DCACHE_DBUG8
  [19:0] PRO_IROM0ADDR_IA
0x414 PRO_DCACHE_DBUG9 — DPORT_PRO_DCACHE_DBUG9
  [19:0] PRO_OPSDRAMADDR_IA
0x418 APP_DCACHE_DBUG0 — DPORT_APP_DCACHE_DBUG0
  [23] APP_RX_END, [22] APP_SLAVE_WDATA_V, [21] APP_SLAVE_WR, [20] APP_TX_END, [19] APP_WR_BAK_TO_READ, [18:7] APP_CACHE_STATE, [6:1] APP_CACHE_IA, [0] APP_CACHE_MMU_IA
0x41C APP_DCACHE_DBUG1 — DPORT_APP_DCACHE_DBUG1
  [31:0] APP_CTAG_RAM_RDATA
0x420 APP_DCACHE_DBUG2 — DPORT_APP_DCACHE_DBUG2
  [26:0] APP_CACHE_VADDR
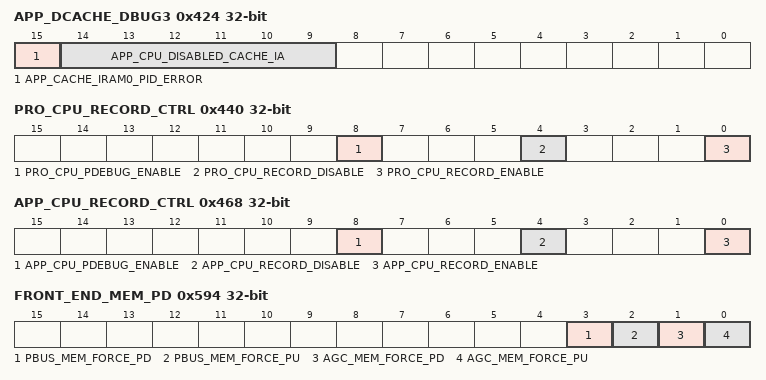
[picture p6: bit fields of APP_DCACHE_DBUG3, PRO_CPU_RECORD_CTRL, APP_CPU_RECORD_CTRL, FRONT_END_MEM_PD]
0x424 APP_DCACHE_DBUG3 — DPORT_APP_DCACHE_DBUG3
  [15] APP_CACHE_IRAM0_PID_ERROR, [14:9] APP_CPU_DISABLED_CACHE_IA
0x428 APP_DCACHE_DBUG4 — DPORT_APP_DCACHE_DBUG4
  [19:0] APP_DRAM1ADDR0_IA
0x42C APP_DCACHE_DBUG5 — DPORT_APP_DCACHE_DBUG5
  [19:0] APP_DROM0ADDR0_IA
0x430 APP_DCACHE_DBUG6 — DPORT_APP_DCACHE_DBUG6
  [19:0] APP_IRAM0ADDR_IA
0x434 APP_DCACHE_DBUG7 — DPORT_APP_DCACHE_DBUG7
  [19:0] APP_IRAM1ADDR_IA
0x438 APP_DCACHE_DBUG8 — DPORT_APP_DCACHE_DBUG8
  [19:0] APP_IROM0ADDR_IA
0x43C APP_DCACHE_DBUG9 — DPORT_APP_DCACHE_DBUG9
  [19:0] APP_OPSDRAMADDR_IA
0x440 PRO_CPU_RECORD_CTRL — DPORT_PRO_CPU_RECORD_CTRL
  [8] PRO_CPU_PDEBUG_ENABLE, [4] PRO_CPU_RECORD_DISABLE, [0] PRO_CPU_RECORD_ENABLE
0x444 PRO_CPU_RECORD_STATUS — DPORT_PRO_CPU_RECORD_STATUS
  [0] PRO_CPU_RECORDING
0x448 PRO_CPU_RECORD_PID — DPORT_PRO_CPU_RECORD_PID
  [2:0] RECORD_PRO_PID
0x44C PRO_CPU_RECORD_PDEBUGINST — DPORT_PRO_CPU_RECORD_PDEBUGINST
  [31:0] RECORD_PRO_PDEBUGINST
0x450 PRO_CPU_RECORD_PDEBUGSTATUS — DPORT_PRO_CPU_RECORD_PDEBUGSTATUS
  [7:0] RECORD_PRO_PDEBUGSTATUS
0x454 PRO_CPU_RECORD_PDEBUGDATA — DPORT_PRO_CPU_RECORD_PDEBUGDATA
  [31:0] RECORD_PRO_PDEBUGDATA
0x458 PRO_CPU_RECORD_PDEBUGPC — DPORT_PRO_CPU_RECORD_PDEBUGPC
  [31:0] RECORD_PRO_PDEBUGPC
0x45C PRO_CPU_RECORD_PDEBUGLS0STAT — DPORT_PRO_CPU_RECORD_PDEBUGLS0STAT
  [31:0] RECORD_PRO_PDEBUGLS0STAT
0x460 PRO_CPU_RECORD_PDEBUGLS0ADDR — DPORT_PRO_CPU_RECORD_PDEBUGLS0ADDR
  [31:0] RECORD_PRO_PDEBUGLS0ADDR
0x464 PRO_CPU_RECORD_PDEBUGLS0DATA — DPORT_PRO_CPU_RECORD_PDEBUGLS0DATA
  [31:0] RECORD_PRO_PDEBUGLS0DATA
0x468 APP_CPU_RECORD_CTRL — DPORT_APP_CPU_RECORD_CTRL
  [8] APP_CPU_PDEBUG_ENABLE, [4] APP_CPU_RECORD_DISABLE, [0] APP_CPU_RECORD_ENABLE
0x46C APP_CPU_RECORD_STATUS — DPORT_APP_CPU_RECORD_STATUS
  [0] APP_CPU_RECORDING
0x470 APP_CPU_RECORD_PID — DPORT_APP_CPU_RECORD_PID
  [2:0] RECORD_APP_PID
0x474 APP_CPU_RECORD_PDEBUGINST — DPORT_APP_CPU_RECORD_PDEBUGINST
  [31:0] RECORD_APP_PDEBUGINST
0x478 APP_CPU_RECORD_PDEBUGSTATUS — DPORT_APP_CPU_RECORD_PDEBUGSTATUS
  [7:0] RECORD_APP_PDEBUGSTATUS
0x47C APP_CPU_RECORD_PDEBUGDATA — DPORT_APP_CPU_RECORD_PDEBUGDATA
  [31:0] RECORD_APP_PDEBUGDATA
0x480 APP_CPU_RECORD_PDEBUGPC — DPORT_APP_CPU_RECORD_PDEBUGPC
  [31:0] RECORD_APP_PDEBUGPC
0x484 APP_CPU_RECORD_PDEBUGLS0STAT — DPORT_APP_CPU_RECORD_PDEBUGLS0STAT
  [31:0] RECORD_APP_PDEBUGLS0STAT
0x488 APP_CPU_RECORD_PDEBUGLS0ADDR — DPORT_APP_CPU_RECORD_PDEBUGLS0ADDR
  [31:0] RECORD_APP_PDEBUGLS0ADDR
0x48C APP_CPU_RECORD_PDEBUGLS0DATA — DPORT_APP_CPU_RECORD_PDEBUGLS0DATA
  [31:0] RECORD_APP_PDEBUGLS0DATA
0x490 RSA_PD_CTRL — DPORT_RSA_PD_CTRL
  [0] RSA_PD
{0x494+4i} ROM_MPU_TABLE{i} (i=0..3) — DPORT_ROM_MPU_TABLE{i}
  [1:0] ROM_MPU_TABLE{i}
{0x4A4+4i} SHROM_MPU_TABLE{i} (i=0..23) — DPORT_SHROM_MPU_TABLE{i}
  [1:0] SHROM_MPU_TABLE{i}
{0x504+4i} IMMU_TABLE{i} (i=0..15) — DPORT_IMMU_TABLE{i}
  [6:0] IMMU_TABLE{i}
{0x544+4i} DMMU_TABLE{i} (i=0..15) — DPORT_DMMU_TABLE{i}
  [6:0] DMMU_TABLE{i}
0x584 PRO_INTRUSION_CTRL — DPORT_PRO_INTRUSION_CTRL
  [0] PRO_INTRUSION_RECORD_RESET_N
0x588 PRO_INTRUSION_STATUS — DPORT_PRO_INTRUSION_STATUS
  [3:0] PRO_INTRUSION_RECORD
0x58C APP_INTRUSION_CTRL — DPORT_APP_INTRUSION_CTRL
  [0] APP_INTRUSION_RECORD_RESET_N
0x590 APP_INTRUSION_STATUS — DPORT_APP_INTRUSION_STATUS
  [3:0] APP_INTRUSION_RECORD
0x594 FRONT_END_MEM_PD — DPORT_FRONT_END_MEM_PD
  [3] PBUS_MEM_FORCE_PD, [2] PBUS_MEM_FORCE_PU, [1] AGC_MEM_FORCE_PD, [0] AGC_MEM_FORCE_PU
0x598 MMU_IA_INT_EN — DPORT_MMU_IA_INT_EN
  [23:0] MMU_IA_INT_EN
0x59C MPU_IA_INT_EN — DPORT_MPU_IA_INT_EN
  [16:0] MPU_IA_INT_EN
0x5A0 CACHE_IA_INT_EN — DPORT_CACHE_IA_INT_EN
  [19] CACHE_IA_INT_PRO_OPPOSITE, [18] CACHE_IA_INT_PRO_DRAM1, [17] CACHE_IA_INT_PRO_IROM0, [16] CACHE_IA_INT_PRO_IRAM1, [15] CACHE_IA_INT_PRO_IRAM0, [14] CACHE_IA_INT_PRO_DROM0, [5] CACHE_IA_INT_APP_OPPOSITE, [3] CACHE_IA_INT_APP_IROM0, [2] CACHE_IA_INT_APP_IRAM1, [1] CACHE_IA_INT_APP_IRAM0, [27:0] CACHE_IA_INT_EN, [0] CACHE_IA_INT_APP_DROM0
0x5A4 SECURE_BOOT_CTRL — DPORT_SECURE_BOOT_CTRL
  [0] SW_BOOTLOADER_SEL
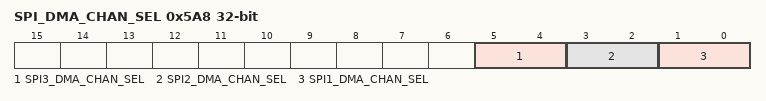
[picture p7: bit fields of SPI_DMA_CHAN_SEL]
0x5A8 SPI_DMA_CHAN_SEL — DPORT_SPI_DMA_CHAN_SEL
  [5:4] SPI3_DMA_CHAN_SEL, [3:2] SPI2_DMA_CHAN_SEL, [1:0] SPI1_DMA_CHAN_SEL
0x5AC PRO_VECBASE_CTRL — DPORT_PRO_VECBASE_CTRL
  [1:0] PRO_OUT_VECBASE_SEL
0x5B0 PRO_VECBASE_SET — DPORT_PRO_VECBASE_SET
  [21:0] PRO_OUT_VECBASE_REG
0x5B4 APP_VECBASE_CTRL — DPORT_APP_VECBASE_CTRL
  [1:0] APP_OUT_VECBASE_SEL
0x5B8 APP_VECBASE_SET — DPORT_APP_VECBASE_SET
  [21:0] APP_OUT_VECBASE_REG
0xFFC DATE — DPORT_DATE
  [27:0] DATE
